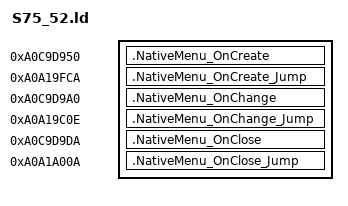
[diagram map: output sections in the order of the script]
SECTIONS {
    .NativeMenu_OnCreate 0xA0C9D950 : {
        KEEP(*(.text.NativeMenu_OnCreate))
    }
    .NativeMenu_OnCreate_Jump 0xA0A19FCA : {
        KEEP(*(.text.NativeMenu_OnCreate_Jump))
    }

    .NativeMenu_OnChange 0xA0C9D9A0 : {
        KEEP(*(.text.NativeMenu_OnChange))
        KEEP(*(.rodata*))
    }
    .NativeMenu_OnChange_Jump 0xA0A19C0E : {
        KEEP(*(.text.NativeMenu_OnChange_Jump))
    }

    .NativeMenu_OnClose 0xA0C9D9DA : {
        KEEP(*(.text.NativeMenu_OnClose))
    }
    .NativeMenu_OnClose_Jump 0xA0A1A00A : {
        KEEP(*(.text.NativeMenu_OnClose_Jump))
    }
}
